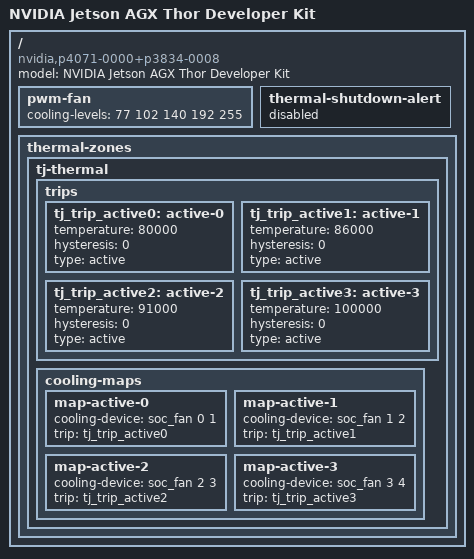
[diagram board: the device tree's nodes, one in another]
// SPDX-License-Identifier: GPL-2.0-only
// SPDX-FileCopyrightText: Copyright (c) 2024-2025, NVIDIA CORPORATION & AFFILIATES.  All rights reserved.
/dts-v1/;

#include "tegra264-p3834-0008.dtsi"
#include "tegra264-p4071-0000.dtsi"

/ {
	model = "NVIDIA Jetson AGX Thor Developer Kit";
	compatible = "nvidia,p4071-0000+p3834-0008", "nvidia,p3834-0008", "nvidia,tegra264";

	pwm-fan {
		cooling-levels = <77 102 140 192 255>;
	};

	thermal-shutdown-alert {
		status = "disabled";
	};

	thermal-zones {
		tj-thermal {
			trips {
				tj_trip_active0: active-0 {
					temperature = <80000>;
					hysteresis = <0>;
					type = "active";
				};

				tj_trip_active1: active-1 {
					temperature = <86000>;
					hysteresis = <0>;
					type = "active";
				};

				tj_trip_active2: active-2 {
					temperature = <91000>;
					hysteresis = <0>;
					type = "active";
				};

				tj_trip_active3: active-3 {
					temperature = <100000>;
					hysteresis = <0>;
					type = "active";
				};
			};

			cooling-maps {
				map-active-0 {
					cooling-device = <&soc_fan 0 1>;
					trip = <&tj_trip_active0>;
				};

				map-active-1 {
					cooling-device = <&soc_fan 1 2>;
					trip = <&tj_trip_active1>;
				};

				map-active-2 {
					cooling-device = <&soc_fan 2 3>;
					trip = <&tj_trip_active2>;
				};

				map-active-3 {
					cooling-device = <&soc_fan 3 4>;
					trip = <&tj_trip_active3>;
				};
			};
		};
	};
};
